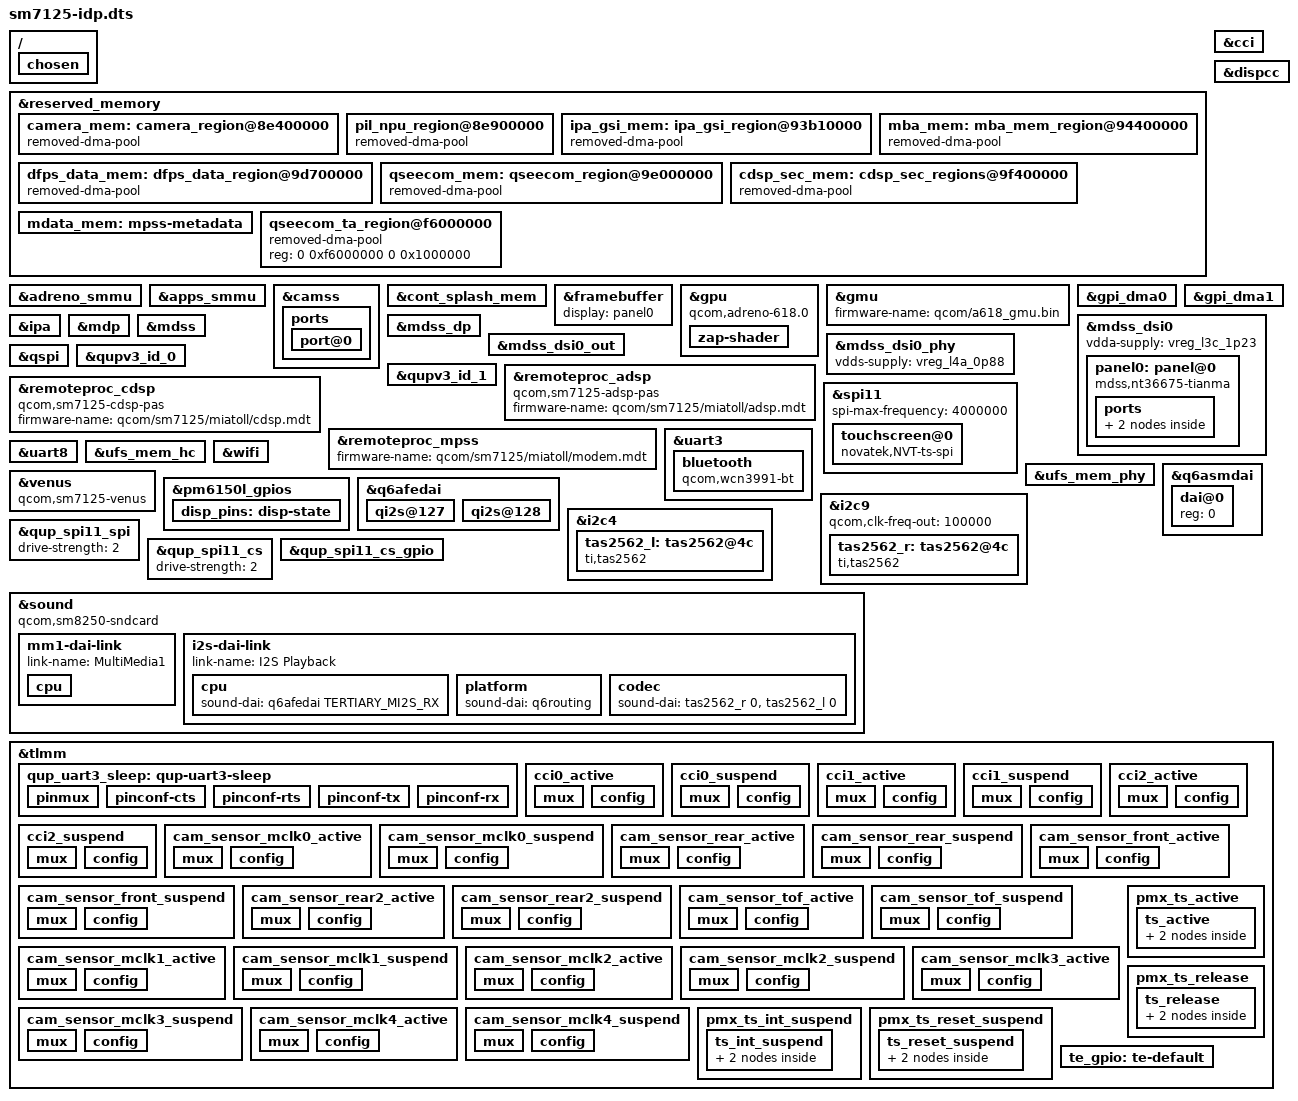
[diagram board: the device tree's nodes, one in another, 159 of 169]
#include "sm7125-xiaomi-joyeuse.dts"
#include "sm7125-idp.dtsi"

/ {
	chosen {
		#address-cells = <2>;
		#size-cells = <2>;
		ranges;

		//TODO: remove unneeded once all sorta out.
		bootargs = "pd_ignore_unused no_console_suspend kpti=off nokaslr ignore_loglevel clk_ignore_unused";

		stdout-path = "serial0:115200n8";
	};

	//reserved_memory: reserved_memory {};
};

&reserved_memory {
		camera_mem: camera_region@8e400000 {
			compatible = "removed-dma-pool";
			no-map;
			reg = <0x00 0x8e400000 0x00 0x500000>;
		};
		
		pil_npu_region@8e900000 {
			compatible = "removed-dma-pool";
			no-map;
			reg = <0x00 0x8e900000 0x00 0x500000>;
		};

		ipa_gsi_mem: ipa_gsi_region@93b10000 {
			compatible = "removed-dma-pool";
			no-map;
			reg = <0x00 0x93b10000 0x00 0x5000>;
		};

		mba_mem: mba_mem_region@94400000 {
			compatible = "removed-dma-pool";
			reg = <0x0 0x94400000 0x0 0x200000>;
			no-map;
		};

		dfps_data_mem: dfps_data_region@9d700000 {
			reg = <0x00 0x9d700000 0x00 0x100000>;
			compatible = "removed-dma-pool";
			no-map;
		};

		qseecom_mem: qseecom_region@9e000000 {
			compatible = "removed-dma-pool";
			no-map;
			reg = <0x00 0x9e000000 0x00 0x1400000>;
		};
		
		cdsp_sec_mem: cdsp_sec_regions@9f400000 {
			compatible = "removed-dma-pool";
			no-map;
			reg = <0x00 0x9f400000 0x00 0x1e00000>;
		};

		mdata_mem: mpss-metadata {
			alloc-ranges = <0x0 0xa0000000 0x0 0x20000000>;
			size = <0x0 0x4000>;
			no-map;
		};

                qseecom_ta_region@f6000000 {
                        compatible = "removed-dma-pool";
                        reg = <0 0xf6000000 0 0x1000000>;
                };
};

&adreno_smmu {
        status = "okay";
};

&apps_smmu {
        status = "okay";
};

&camss {
	//vdda-phy-supply = <&vreg_l1a_0p875>;
	//vdda-pll-supply = <&vreg_l26a_1p2>;

	status = "okay";

	ports {
		port@0 {
#if 0
			csiphy0_ep: endpoint {
				data-lanes = <0 1 2 3>;
				//remote-endpoint = <&ov8856_ep>;
			};
#endif
		};
	};
};

&cci {
        status = "okay";
};

&cont_splash_mem {
//	compatible = "shared-dma-pool";
};

&dispcc {
	status = "okay";
};

&framebuffer {
        display = <&panel0>;
        status = "okay";
};


&gpu {
	compatible = "qcom,adreno-618.0", "qcom,adreno";
	firmware-name = "qcom/sm7125/miatoll/a615_zap.mbn";

	status = "okay";

	zap-shader {
			memory-region = <&gpu_mem>;
			firmware-name = "qcom/sm7125/miatoll/a615_zap.mbn";
	};
};

&gmu {
	firmware-name = "qcom/a618_gmu.bin";
	status = "okay";
};

&gpi_dma0 {
	status = "okay";
};

&gpi_dma1 {
	status = "okay";
};

&ipa {
	memory-region = <&ipa_fw_mem>;
	firmware-name = "qcom/sm7125/miatoll/ipa_fws.mbn";

	status = "okay";
};

&mdp {
	// TODO: check if mdss or mdp hold this memory
//	memory-region = <&cont_splash_mem>;

	status = "okay";
};

&mdss {
	// TODO: check if mdss or mdp hold this memory
//	memory-region = <&cont_splash_mem>;
	status = "okay";
};

&mdss_dp {
        status = "okay";
};

&mdss_dsi0 {
	vdda-supply = <&vreg_l3c_1p23>;
	status = "okay";

	panel0: panel@0 {
	};
};

&mdss_dsi0_out {
	remote-endpoint = <&panel0_in>;
	data-lanes = <0 1 2 3>;

	status = "okay";
};

&mdss_dsi0_phy {
	vdds-supply = <&vreg_l4a_0p88>;

	status = "okay";
};

&panel0 {
	compatible = "mdss,nt36675-tianma", 
			"mdss,nt36675-tianma-fhd";

	reg = <0>;
	
	/* TODO: check vreg l3c/l3a */
	//vdda-supply = <&vreg_l3c_1p23>; //from downstream, need to double check
	//vdd3p3-supply = <&vreg_l18a_3p0>;
	//vddio-supply = <&vreg_l13a_1p8>; //from sm7150-xiaomi-common.dtsi
	vddio-supply = <&vreg_l18a_3p0>;

#if 0
	/* 
		display_sde.dtsi
			vddio-supply = <&L13A>;
			vdda-3p3-supply = <&L18A>;
		---
		cust-atoll-sde-display.dtsi
			/delete-property/ vdda-3p3-supply;

		        vddio-supply = <&L18A>;
	*/

	lab-supply = <&lab>;
	ibb-supply = <&ibb>;
#endif
	//backlight = <&pm6150l_wled>;

	pinctrl-names = "default", "te_pin"; //TODO: need to figure out how to handle te_pin
	pinctrl-0 = <&disp_pins>;
        pinctrl-1 = <&te_gpio>;

	/* according to panel-nt36675-tianma.c this gpio is finally set to low */
	reset-gpios = <&pm6150l_gpios 3 GPIO_ACTIVE_LOW>;
	//disp-te-gpio = <&tlmm 10 GPIO_ACTIVE_LOW>;

	status = "okay";

	ports {
		#address-cells = <1>;
		#size-cells = <0>;
		port@0 {
			reg = <0>;
			panel0_in: endpoint {
				remote-endpoint = <&mdss_dsi0_out>;
			};
		};
	};
};


&qspi {
	pinctrl-names = "default";
	pinctrl-0 = <&qspi_clk &qspi_cs0 &qspi_data0 &qspi_data1>;
	
	status = "okay";
};

&qupv3_id_0 {
	status = "okay";
};

&qupv3_id_1 {
	status = "okay";
};

&remoteproc_adsp {
	compatible = "qcom,sm7125-adsp-pas", "qcom,sc7280-adsp-pas";
	firmware-name = "qcom/sm7125/miatoll/adsp.mdt";

	status = "okay";
};

&remoteproc_cdsp {
	compatible = "qcom,sm7125-cdsp-pas", "qcom,sc7280-cdsp-pas";
	firmware-name = "qcom/sm7125/miatoll/cdsp.mdt";

	status = "okay";
};

&remoteproc_mpss {
        firmware-name = "qcom/sm7125/miatoll/modem.mdt";
		
        status = "okay";
};

&spi11 {
	spi-max-frequency = <4000000>;
	status = "okay";

	//nt36xxx_touch: i2c@
	touchscreen@0 {
		compatible = "novatek,NVT-ts-spi", "novatek,NVT-ts-spi", "novatek,nt36675-spi";
		reg = <0>;

		spi-max-frequency = <4000000>;

		//interrupts = <&tlmm 41 IRQ_TYPE_EDGE_FALLING>;

		novatek,reset-gpio = <&tlmm 8 0x00>;
		novatek,irq-gpio = <&tlmm 9 0x2001>;

		/* 672C */
		novatek,swrst-n8-addr = <0x03F0FE>;
		novatek,spi-rd-fast-addr = <0x03F310>;

		reset-gpio = <&tlmm 8 0x00>;
		irq-gpio = <&tlmm 9 0x2001>;

		panel = <&panel0>;

		status = "okay";
	};
};

&uart3 {
	/delete-property/interrupts;
	interrupts-extended = <&intc GIC_SPI 604 IRQ_TYPE_LEVEL_HIGH>,
				<&tlmm 41 IRQ_TYPE_EDGE_FALLING>;

	pinctrl-names = "default", "sleep";
	pinctrl-1 = <&qup_uart3_sleep>;
	status = "okay";
	
	bluetooth: bluetooth {
		compatible = "qcom,wcn3991-bt";

		//TODO: add firmware support here
		//firmware-name = "qcom/sm7125/crnv21.bin";

		vddio-supply = <&vreg_l10a_1p8>;
		vddxo-supply = <&vreg_l1c_1p8>;
		vddrf-supply = <&vreg_l2c_1p3>;
		vddch0-supply = <&vreg_l10c_3p3>;
		max-speed = <3200000>;
		status = "okay";
	};
};

&uart8 {
	status = "okay";
};


&ufs_mem_hc {
	vcc-supply = <&vreg_l19a_3p0>;
	vcc-max-microamp = <600000>;
	vccq2-supply = <&vreg_l12a_1p8>;
	vccq2-max-microamp = <600000>;

	status = "okay";
};

&ufs_mem_phy {
	vdda-phy-supply = <&vreg_l4a_0p88>;
	vdda-pll-supply = <&vreg_l3c_1p23>;
	vdda-phy-max-microamp = <62900>;
	vdda-pll-max-microamp = <18300>;

	status = "okay";
};


&venus {
	compatible = "qcom,sm7125-venus", "qcom,sc7180-venus";
	memory-region = <&venus_mem>;

	firmware-name = "qcom/sm7125/miatoll/venus.mbn";

	status = "okay";
#if 0
	video-firmware {
		iommus = <&apps_smmu 0x0c42 0x0>;
		firmware-name = "qcom/sm7125/miatoll/venus.mbn";
	};
#endif
};

&wifi {
	vdd-0.8-cx-mx-supply = <&vreg_l9a_0p664>;
	vdd-1.8-xo-supply = <&vreg_l1c_1p8>;
	vdd-1.3-rfa-supply = <&vreg_l2c_1p3>;
	vdd-3.3-ch0-supply = <&vreg_l10c_3p3>;
	vdd-3.3-ch1-supply = <&vreg_l11c_3p3>;

        status = "okay";
/*
	wifi-firmware {
		iommus = <&apps_smmu 0xc2 0x1>;
	};
*/
};

/* PINCTRL - additions to nodes defined in sc7180.dtsi */
&pm6150l_gpios {
	disp_pins: disp-state {
		pins = "gpio3";
		function = PMIC_GPIO_FUNC_FUNC1;
		qcom,drive-strength = <PMIC_GPIO_STRENGTH_MED>;
		power-source = <0>;
		bias-disable;
		output-low;
	};

};

&q6afedai {
        qi2s@127 {
                reg = <QUINARY_MI2S_RX>;
                qcom,sd-lines = <0>;
        };

        qi2s@128 {
                reg = <QUINARY_MI2S_TX>;
                qcom,sd-lines = <1>;
        };
};

&q6asmdai {
        dai@0 {
                reg = <0>;
        };
};


&i2c9 {
        status = "ok";

        qcom,clk-freq-out = <100000>;

        tas2562_r: tas2562@4c {
                #sound-dai-cells = <0>;
                compatible = "ti,tas2562";
                reg = <0x4c>;
                ti,left-channel = <0x4c>; /* addr */
                ti,channels = <1>; /* channel number */
                ti,asi-format = <0>; /* 0, i2S; 1, DSP;  */
                ti,reset-gpio = <&tlmm 51 0>;
                ti,irq-gpio = <&tlmm 33 0>;
                ti,left-slot = <0>; /* <left slot number> */
                ti,right-slot = <1>; /* <right slot number> */
                ti,imon-slot-no = <0>; /* <current sense slot number> */
                ti,vmon-slot-no = <2>; /* <current voltage slot number> */
                status = "ok";
        };
};

&i2c4 {
        status = "ok";

        tas2562_l: tas2562@4c {
                #sound-dai-cells = <0>;
                compatible = "ti,tas2562";
                reg = <0x4c>;
                ti,left-channel = <0x4c>; /* addr */
                ti,channels = <1>; /* channel number */
                ti,asi-format = <0>; /* 0, i2S; 1, DSP;  */
                ti,reset-gpio = <&tlmm 51 0>;
                ti,irq-gpio = <&tlmm 33 0>;
                ti,left-slot = <0>; /* <left slot number> */
                ti,right-slot = <1>; /* <right slot number> */
                ti,imon-slot-no = <0>; /* <current sense slot number> */
                ti,vmon-slot-no = <2>; /* <current voltage slot number> */
                status = "ok";
        };
};

&qup_spi11_spi {
	drive-strength = <2>;
	//bias-disable;
};

&qup_spi11_cs {
	drive-strength = <2>;
	//bias-disable;
};

&qup_spi11_cs_gpio {
	drive-strength = <2>;
	bias-disable;
};

&sound {
        compatible = "qcom,sm8250-sndcard";
        pinctrl-0 = <&i2s2_active>;
        pinctrl-names = "default";
        model = "Miatoll";

        mm1-dai-link {
                link-name = "MultiMedia1";
                cpu {
                        sound-dai = <&q6asmdai MSM_FRONTEND_DAI_MULTIMEDIA1>;
                };
        };

        i2s-dai-link {
                link-name = "I2S Playback";
                cpu {
			/*TODO: tertery */
                        sound-dai = <&q6afedai TERTIARY_MI2S_RX>;
                };

                platform {
                        sound-dai = <&q6routing>;
                };

                codec {
                        sound-dai = <&tas2562_r 0>, <&tas2562_l 0>;
                };
        };
};

&tlmm {
	qup_uart3_sleep: qup-uart3-sleep {
		pinmux {
			pins = "gpio38", "gpio39",
			       "gpio40", "gpio41";
			function = "gpio";
		};

		pinconf-cts {
			/*
			 * Configure a pull-down on CTS to match the pull of
			 * the Bluetooth module.
			 */
			pins = "gpio38";
			bias-pull-down;
		};

		pinconf-rts {
			/*
			 * Configure pull-down on RTS. As RTS is active low
			 * signal, pull it low to indicate the BT SoC that it
			 * can wakeup the system anytime from suspend state by
			 * pulling RX low (by sending wakeup bytes).
			 */
			 pins = "gpio39";
			 bias-pull-down;
		};

		pinconf-tx {
			/*
			 * Configure pull-up on TX when it isn't actively driven
			 * to prevent BT SoC from receiving garbage during sleep.
			 */
			pins = "gpio40";
			bias-pull-up;
		};

		pinconf-rx {
			/*
			 * Configure a pull-up on RX. This is needed to avoid
			 * garbage data when the TX pin of the Bluetooth module
			 * is floating which may cause spurious wakeups.
			 */
			pins = "gpio41";
			bias-pull-up;
		};
	};

		cci0_active: cci0_active {
			mux {
				/* CLK, DATA */
				pins = "gpio17", "gpio18";
				function = "cci_i2c";
			};

			config {
				pins = "gpio17", "gpio18";
				bias-pull-up; /* PULL UP*/
				drive-strength = <2>; /* 2 MA */
			};
		};

		cci0_suspend: cci0_suspend {
			mux {
				/* CLK, DATA */
				pins = "gpio17", "gpio18";
				function = "cci_i2c";
			};

			config {
				pins = "gpio17", "gpio18";
				bias-pull-down; /* PULL DOWN */
				drive-strength = <2>; /* 2 MA */
			};
		};

		cci1_active: cci1_active {
			mux {
				/* CLK, DATA */
				pins = "gpio19", "gpio20";
				function = "cci_i2c";
			};

			config {
				pins = "gpio19", "gpio20";
				bias-pull-up; /* PULL UP*/
				drive-strength = <2>; /* 2 MA */
			};
		};

		cci1_suspend: cci1_suspend {
			mux {
				/* CLK, DATA */
				pins = "gpio19", "gpio20";
				function = "cci_i2c";
			};

			config {
				pins = "gpio19", "gpio20";
				bias-pull-down; /* PULL DOWN */
				drive-strength = <2>; /* 2 MA */
			};
		};

		cci2_active: cci2_active {
			mux {
				/* CLK, DATA */
				pins = "gpio27", "gpio28";
				function = "cci_i2c";
			};

			config {
				pins = "gpio27", "gpio28";
				bias-pull-up; /* PULL UP*/
				drive-strength = <2>; /* 2 MA */
			};
		};

		cci2_suspend: cci2_suspend {
			mux {
				/* CLK, DATA */
				pins = "gpio27", "gpio28";
				function = "cci_i2c";
			};

			config {
				pins = "gpio27", "gpio28";
				bias-pull-down; /* PULL DOWN */
				drive-strength = <2>; /* 2 MA */
			};
		};

		cam_sensor_mclk0_active: cam_sensor_mclk0_active {
			/* MCLK0 */
			mux {
				pins = "gpio13";
				function = "cam_mclk";
			};

			config {
				pins = "gpio13";
				bias-disable; /* No PULL */
				drive-strength = <2>; /* 2 MA */
			};
		};

		cam_sensor_mclk0_suspend: cam_sensor_mclk0_suspend {
			/* MCLK0 */
			mux {
				pins = "gpio13";
				function = "cam_mclk";
			};

			config {
				pins = "gpio13";
				bias-pull-down; /* PULL DOWN */
				drive-strength = <2>; /* 2 MA */
			};
		};

		cam_sensor_rear_active: cam_sensor_rear_active {
			/* RESET */
			mux {
				pins = "gpio30";
				function = "gpio";
			};

			config {
				pins = "gpio30";
				bias-disable; /* No PULL */
				drive-strength = <2>; /* 2 MA */
			};
		};

		cam_sensor_rear_suspend: cam_sensor_rear_suspend {
			/* RESET */
			mux {
				pins = "gpio30";
				function = "gpio";
			};

			config {
				pins = "gpio30";
				bias-pull-down; /* PULL DOWN */
				drive-strength = <2>; /* 2 MA */
				output-low;
			};
		};

		cam_sensor_front_active: cam_sensor_front_active {
			/* RESET  */
			mux {
				pins = "gpio29";
				function = "gpio";
			};

			config {
				pins = "gpio29";
				bias-disable; /* No PULL */
				drive-strength = <2>; /* 2 MA */
			};
		};

		cam_sensor_front_suspend: cam_sensor_front_suspend {
			/* RESET */
			mux {
				pins = "gpio29";
				function = "gpio";
			};

			config {
				pins = "gpio29";
				bias-pull-down; /* PULL DOWN */
				drive-strength = <2>; /* 2 MA */
				output-low;
			};
		};

		cam_sensor_rear2_active: cam_sensor_rear2_active {
			/* RESET */
			mux {
				pins = "gpio25";
				function = "gpio";
			};

			config {
				pins = "gpio25";
				bias-disable; /* No PULL */
				drive-strength = <2>; /* 2 MA */
			};
		};

		cam_sensor_rear2_suspend: cam_sensor_rear2_suspend {
			/* RESET */
			mux {
				pins = "gpio25";
				function = "gpio";
			};

			config {
				pins = "gpio25";
				bias-pull-down; /* PULL DOWN */
				drive-strength = <2>; /* 2 MA */
				output-low;
			};
		};

		cam_sensor_tof_active: cam_sensor_tof_active {
			/* RESET */
			mux {
				pins = "gpio24";
				function = "gpio";
			};

			config {
				pins = "gpio24";
				bias-disable; /* No PULL */
				drive-strength = <2>; /* 2 MA */
			};
		};

		cam_sensor_tof_suspend: cam_sensor_tof_suspend {
			/* RESET */
			mux {
				pins = "gpio24";
				function = "gpio";
			};

			config {
				pins = "gpio24";
				bias-pull-down; /* PULL DOWN */
				drive-strength = <2>; /* 2 MA */
				output-low;
			};
		};

		cam_sensor_mclk1_active: cam_sensor_mclk1_active {
			/* MCLK1 */
			mux {
				pins = "gpio14";
				function = "cam_mclk";
			};

			config {
				pins = "gpio14";
				bias-disable; /* No PULL */
				drive-strength = <2>; /* 2 MA */
			};
		};

		cam_sensor_mclk1_suspend: cam_sensor_mclk1_suspend {
			/* MCLK1 */
			mux {
				pins = "gpio14";
				function = "cam_mclk";
			};

			config {
				pins = "gpio14";
				bias-pull-down; /* PULL DOWN */
				drive-strength = <2>; /* 2 MA */
			};
		};

		cam_sensor_mclk2_active: cam_sensor_mclk2_active {
			/* MCLK2 */
			mux {
				pins = "gpio15";
				function = "cam_mclk";
			};

			config {
				pins = "gpio15";
				bias-disable; /* No PULL */
				drive-strength = <2>; /* 2 MA */
			};
		};

		cam_sensor_mclk2_suspend: cam_sensor_mclk2_suspend {
			/* MCLK2 */
			mux {
				pins = "gpio15";
				function = "cam_mclk";
			};

			config {
				pins = "gpio15";
				bias-pull-down; /* PULL DOWN */
				drive-strength = <2>; /* 2 MA */
			};
		};

		cam_sensor_mclk3_active: cam_sensor_mclk3_active {
			/* MCLK3 */
			mux {
				pins = "gpio16";
				function = "cam_mclk";
			};

			config {
				pins = "gpio16";
				bias-disable; /* No PULL */
				drive-strength = <2>; /* 2 MA */
			};
		};

		cam_sensor_mclk3_suspend: cam_sensor_mclk3_suspend {
			/* MCLK3 */
			mux {
				pins = "gpio16";
				function = "cam_mclk";
			};

			config {
				pins = "gpio16";
				bias-pull-down; /* PULL DOWN */
				drive-strength = <2>; /* 2 MA */
			};
		};

		cam_sensor_mclk4_active: cam_sensor_mclk4_active {
			/* MCLK4 */
			mux {
				pins = "gpio23";
				function = "cam_mclk";
			};

			config {
				pins = "gpio23";
				bias-disable; /* No PULL */
				drive-strength = <2>; /* 2 MA */
			};
		};

		cam_sensor_mclk4_suspend: cam_sensor_mclk4_suspend {
			/* MCLK4 */
			mux {
				pins = "gpio23";
				function = "cam_mclk";
			};

			config {
				pins = "gpio23";
				bias-pull-down; /* PULL DOWN */
				drive-strength = <2>; /* 2 MA */
			};
		};

        pmx_ts_active {
                ts_active: ts_active {
                                mux {
                                        pins = "gpio8", "gpio9";
                                        function = "gpio";
                                };

                                config {
                                        pins = "gpio8", "gpio9";
                                        drive-strength = <8>;
                                        bias-pull-up;
                                };
                        };
        };

                pmx_ts_int_suspend {
                        ts_int_suspend: ts_int_suspend {
                                mux {
                                        pins = "gpio9";
                                        function = "gpio";
                                };

                                config {
                                        pins = "gpio9";
                                        drive-strength = <2>;
                                        bias-disable;
                                };
                        };
                };

                pmx_ts_reset_suspend {
                        ts_reset_suspend: ts_reset_suspend {
                                mux {
                                        pins = "gpio8";
                                        function = "gpio";
                                };

                                config {
                                        pins = "gpio8";
                                        drive-strength = <2>;
                                        bias-disable;
                                };
                        };
                };

                pmx_ts_release {
                        ts_release: ts_release {
                                mux {
                                        pins = "gpio9", "gpio8";
                                        function = "gpio";
                                };

                                config {
                                        pins = "gpio9", "gpio8";
                                        drive-strength = <2>;
                                        bias-disable;
                                };
                        };
                };

        te_gpio: te-default {
                pins = "gpio10";
                function = "mdp_vsync";
                drive-strength = <2>;   /* 2 mA */
                bias-pull-down;         /* PULL DOWN */
        };
};


